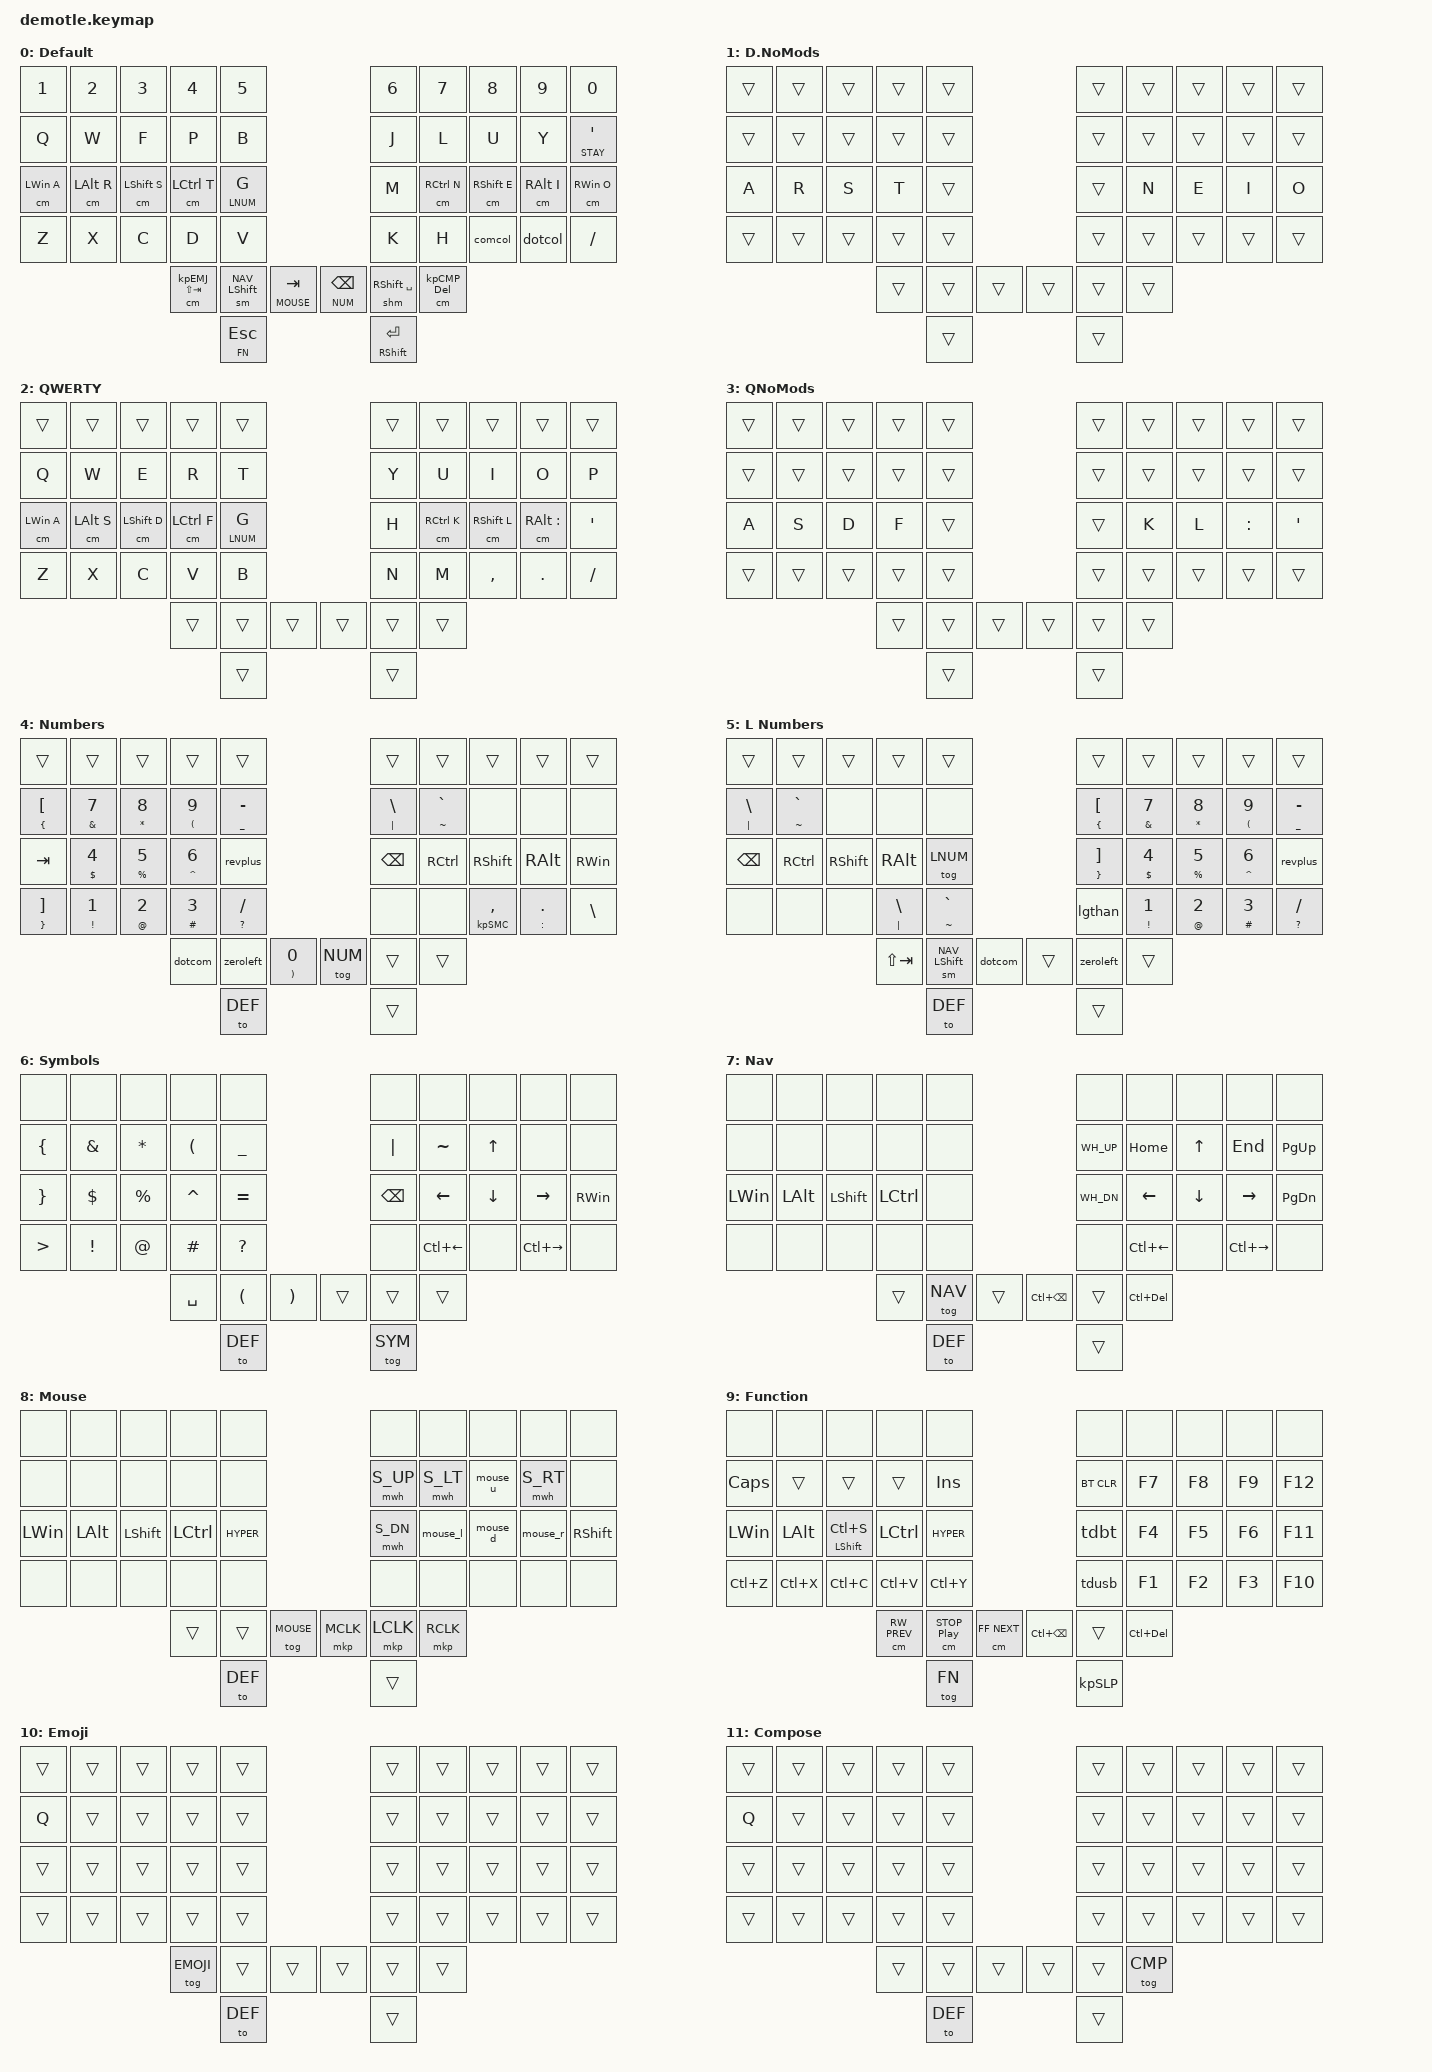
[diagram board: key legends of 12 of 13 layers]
/*
 * Copyright (c) 2023 Tom Butcher
 *
 * SPDX-License-Identifier: MIT
 */

 // standard build command: west build -b nice_nano_v2 -- -DSHIELD=demotle

 /* ********* TO DO *************
	* Once unicode works, create macros that change the layer and send the appropriate F key
	  (for helper image) at the same time.
 */

#include <behaviors.dtsi>
#include <dt-bindings/zmk/keys.h>
#include <dt-bindings/zmk/bt.h>
#include <dt-bindings/zmk/outputs.h>
#include <dt-bindings/zmk/ext_power.h>

// Layer Defs
#define DEF		0
#define DEF_NM	1
#define QWERTY	2
#define QWER_NM	3
#define NUM		4
#define LNUM	5
#define SYM		6
#define NAV		7
#define MOUSE	8
#define FN		9	
#define EMOJI	10	// Reserved for future use 
#define CMP		11	// Reserved for future use
#define STAY	12

// Mouse Key defs--For use until AHK can be ditched
#define WH_DN	(F16)
#define WH_UP	(F17)
// #define WH_L	(KP_N7)
// #define WH_R	(KP_N9)
// #define M_UP	(KP_N8)
// #define M_DN	(KP_N5)
// #define M_L		(KP_N4)
// #define M_R		(KP_N6)
// #define M_UP_SL	(LC(LG(LA(M_UP))))		// These move the mouse slowly
// #define M_DN_SL	(LC(LG(LA(M_DN))))
// #define M_R_SL	(LC(LG(LA(M_R))))
// #define M_L_SL	(LC(LG(LA(M_L))))
// #define M_MB	(KP_DIVIDE)
// #define M_LB	(KP_MINUS)
// #define M_RB	(KP_MULTIPLY)

// F Key subs (use with AHK)
#define KP_PLS	(F18)
#define KP_COM	(F19)
#define KP_SMC	(F20)
#define KP_EMJ	(F21)
#define KP_CMP	(F23)
#define KP_SLP	(LG(LA(LS(LC(APOS)))))

// Other defs
#define xxx		&none	
#define ___		&trans
#define HYPER	(LG(LA(LS(LCTRL))))		  // If I want to send a hypered key, then I might need to make a custom behavior
// #define HYPER	(LG(LA(LS(LCTRL))))   // Maybe try to make a custom mod kp?

#include <../boards/shields/space_invader/key_positions.h>
#include <../boards/shields/space_invader/mouse.dtsi>
#include <../boards/shields/space_invader/helper.h>
#include <../boards/shields/space_invader/behaviors.dtsi>
#include <../boards/shields/space_invader/combos.dtsi>

&mt { quick_tap_ms = <200>; };
&lt { quick_tap_ms = <200>; };

/ {
	conditional_layers {
        compatible = "zmk,conditional-layers";
        tri_layer {
            if-layers = <1 2>;
            then-layer = <3>;
        };
    };

	keymap {
		compatible = "zmk,keymap";

							// -------------------------------------------------TEMPLATE-------------------------------------------------
							// |      |      |      |      |      |                                  |      |      |      |      |      |
							// |      |      |      |      |      |                                  |      |      |      |      |      |
							// |      |      |      |      |      |             |      |             |      |      |      |      |      |
							// |      |------|      |      |      |      |      	          |      |      |      |      |------|      |
							// |----------------------------------|      |      |      |      |      |----------------------------------|
							// ----------------------------------------------------------------------------------------------------------

//------------------------------------------------------------------------------------------------EMPTY TEMPLATE-----------------------------------------------------------------------------------------------\\

//╭───────────────┬───────────────┬───────────────┬───────────────┬───────────────╮									  ╭───────────────┬───────────────┬───────────────┬───────────────┬───────────────╮

//├───────────────┼───────────────┼───────────────┼───────────────┼───────────────┤									  ├───────────────┼───────────────┼───────────────┼───────────────┼───────────────┤

//├───────────────┼───────────────┼───────────────┼───────────────┼───────────────┤									  ├───────────────┼───────────────┼───────────────┼───────────────┼───────────────┤

//├───────────────┼───────────────┼───────────────┼───────────────┼───────────────┤									  ├───────────────┼───────────────┼───────────────┼───────────────┼───────────────┤

//╰───────────────┴───────────────┴───────────────┼───────────────┼───────────────╰───────────────╮	  ╭───────────────╯───────────────┼───────────────┼───────────────┴───────────────┴───────────────╯
											 
//												  ╰───────────────┼───────────────┼───────────────╯	  ╰───────────────┼───────────────┼───────────────╯

//														  		  ╰───────────────╯									  ╰───────────────╯



		default_layer { 
			label = "Default";
			// -------------------------------------------------COLEMAK--------------------------------------------------
			// |  Q   |  W   |  F   |  P   |  B   |                                  |  J   |  L   |  U   |  Y   |  '"  |
			// |  A   |  R   |  S   |  T   |  G   |                                  |  M   |  N   |  E   |  I   |  O   |
			// |  Z   |  X   |  C   |  D   |  V   |             | Mute |             |  K   |  H   |  ,;  |  .:  |  /?  |  // In the future, maybe change back to interobang
			// |  Esc |------| Home |ShftTb|StckSh| Tab  |      	          | Bspc | Space| Del  |  End |------|  Del |  // Although maybe slash is more common than exclamation mark?
			// |----------------------------------|  Up  | Left | Enter| Right| Down |----------------------------------|
			// ----------------------------------------------------------------------------------------------------------
			// ------------------------------------------------HOLD LAYER------------------------------------------------
			// |      |      |      |      |      |                                  |      |      |      |      | Stay |
			// | LWin | LAlt | LShft| LCtrl| LNum |                                  |      | RCtrl| RShft| RAlt | RWin |
			// |      |      |      |      |      |             |      |             |      |      |      |      |      |
			// |  Fn  |------| LCtrl| Emoji| Nav  | Mouse|      	          | Num  | RShft| Cmp  | Sym  |------| Media|
			// |----------------------------------|      |      |      |      |      |----------------------------------|
			// ----------------------------------------------------------------------------------------------------------

			bindings = <
//-----------------------------------------------------------------------------------------------COLEMAK---------------------------------------------------------------------------------------------\\

//╭───────────────┬───────────────┬───────────────┬───────────────┬───────────────╮									  ╭───────────────┬───────────────┬───────────────┬───────────────┬───────────────╮
	&kp N1			&kp N2			&kp N3			&kp N4			&kp N5												&kp N6			&kp N7			&kp N8			&kp N9			&kp N0
//├───────────────┼───────────────┼───────────────┼───────────────┼───────────────┤									  ├───────────────┼───────────────┼───────────────┼───────────────┼───────────────┤
	&kp Q			&kp W			&kp F			&kp P			&kp B												&kp J			&kp L			&kp U			&kp Y			&lt STAY APOS	// &tdq
//├───────────────┼───────────────┼───────────────┼───────────────┼───────────────┤									  ├───────────────┼───────────────┼───────────────┼───────────────┼───────────────┤
	&cm LWIN A		&cm LALT R		&cm LSHFT S		&cm LCTRL T		&lt LNUM G											&kp M			&cm RCTRL N		&cm RSHFT E		&cm RALT I		&cm RWIN O
//├───────────────┼───────────────┼───────────────┼───────────────┼───────────────┤									  ├───────────────┼───────────────┼───────────────┼───────────────┼───────────────┤
	&kp Z			&kp X			&kp C			&kp D			&kp V												&kp K			&kp H			&comcol			&dotcol			&kp SLASH
//╰───────────────┴───────────────┴───────────────┼───────────────┼───────────────╰───────────────╮	  ╭───────────────╯───────────────┼───────────────┼───────────────┴───────────────┴───────────────╯
												&cm KP_EMJ LS(TAB)	&sm NAV LSHFT 	&lt MOUSE TAB		&lt NUM BSPC	&shm RSHFT SPACE &cm KP_CMP DEL
//												  ╰───────────────┼───────────────┼───────────────╯	  ╰───────────────┴───────────────┴───────────────╯
																	&lt FN ESC											&mt RSHFT RET
//																  ╰───────────────╯									  ╰───────────────╯

			>;
		};

		default_no_mods_layer { // Just turns off homerow mods, so no need for the whole keymap diagram
			label = "D.NoMods";
			bindings = <___ ___ ___ ___ ___ ___ ___ ___ ___ ___
						___ ___ ___ ___ ___ ___ ___ ___ ___ ___
						&kp A &kp R &kp S &kp T ___ ___ &kp N &kp E &kp I &kp O
						___ ___ ___ ___ ___ ___ ___ ___ ___ ___
						___ ___ ___ ___ ___ ___ ___ ___>;
		};

		qwerty_layer {
			label = "QWERTY";
			bindings = <
//-----------------------------------------------------------------------------------------------QWERTY----------------------------------------------------------------------------------------------\\

//╭───────────────┬───────────────┬───────────────┬───────────────┬───────────────╮									  ╭───────────────┬───────────────┬───────────────┬───────────────┬───────────────╮
	___				___				___				___				___													___				___				___				___				___
//├───────────────┼───────────────┼───────────────┼───────────────┼───────────────┤									  ├───────────────┼───────────────┼───────────────┼───────────────┼───────────────┤
	&kp Q			&kp W			&kp E			&kp R			&kp T												&kp Y			&kp U			&kp I			&kp O			&kp P 			// &lt STAY APOS
//├───────────────┼───────────────┼───────────────┼───────────────┼───────────────┤									  ├───────────────┼───────────────┼───────────────┼───────────────┼───────────────┤
	&cm LWIN A		&cm LALT S		&cm LSHFT D		&cm LCTRL F		&lt LNUM G											&kp H			&cm RCTRL K		&cm RSHFT L		&cm RALT COLON 	&kp APOS
//├───────────────┼───────────────┼───────────────┼───────────────┼───────────────┤									  ├───────────────┼───────────────┼───────────────┼───────────────┼───────────────┤
	&kp Z			&kp X			&kp C			&kp V			&kp B												&kp N			&kp M			&kp COMMA		&kp DOT			&kp SLASH
//╰───────────────┴───────────────┴───────────────┼───────────────┼───────────────╰───────────────╮	  ╭───────────────╯───────────────┼───────────────┼───────────────┴───────────────┴───────────────╯
													___				___				___					___				___				___
//												  ╰───────────────┼───────────────┼───────────────╯	  ╰───────────────┴───────────────┴───────────────╯
																	___													___
//																  ╰───────────────╯									  ╰───────────────╯

			>;
		};

		qwerty_no_mods_layer { // Just turns off homerow mods, so no need for the whole keymap diagram
			label = "QNoMods";
			bindings = <___ ___ ___ ___ ___ ___ ___ ___ ___ ___
						___ ___ ___ ___ ___ ___ ___ ___ ___ ___
						&kp A &kp S &kp D &kp F ___ ___ &kp K &kp L &kp COLON &kp APOS
						___ ___ ___ ___ ___ ___ ___ ___ ___ ___
						___ ___ ___ ___ ___ ___ ___ ___ >;
		};

		number_layer {
			label = "Numbers";
			
			// --------------------------------------------------NUMBER--------------------------------------------------
			// |  [{  |  1!  |  2@  |  3#  |  -_  |                                  |      |  \|  |  `~  |      |      |
			// |  ]}  |  4$  |  5%  |  6^  |  =+  |                                  | BSPC | RCTRL| RSHFT| RALT | RWIN |
			// |  <>  |  7&  |  8*  |  9(  |  \|  |             |      |             |      |      |  ,;  |  .:  |      |
			// | DEF |------| SPACE|  .,  |  0(  |  0)  |      	          |      |      |      |      |------|      |
			// |----------------------------------|      |      |      |      |      |----------------------------------|
			// ----------------------------------------------------------------------------------------------------------

			bindings = < // All numbers use auto-shift for symbols
//---------------------------------------------------------------------------------------------------NUMBERS--------------------------------------------------------------------------------------------------\\

//╭───────────────┬───────────────┬───────────────┬───────────────┬───────────────╮								  ╭───────────────┬───────────────┬───────────────┬───────────────┬───────────────╮
	___			  ___			___			  ___			___																			  ___			___			  ___			___			  ___
//├───────────────┼───────────────┼───────────────┼───────────────┼───────────────┤								  ├───────────────┼───────────────┼───────────────┼───────────────┼───────────────┤
  	&as LBRC LBKT &as AMPS N7	&as ASTRK N8  &as LPAR N9 	&as UNDER MINUS																  &as PIPE BSLH &as TILDE GRAVE xxx		  	xxx			  xxx
//├───────────────┼───────────────┼───────────────┼───────────────┼───────────────┤								  ├───────────────┼───────────────┼───────────────┼───────────────┼───────────────┤
  	&kp TAB		  &as DLLR N4	&as PRCNT N5  &as CARET N6	&revplus																	  &kp BSPC		&kp RCTRL	  &kp RSHFT		&kp RALT	  &kp RWIN
//├───────────────┼───────────────┼───────────────┼───────────────┼───────────────┤								  ├───────────────┼───────────────┼───────────────┼───────────────┼───────────────┤
	&as RBRC RBKT &as EXCL N1	&as AT N2	  &as HASH N3	&as QMARK SLASH																  xxx			xxx		   &as KP_SMC COMMA &as COLON DOT &kp BSLH
//╰───────────────┴───────────────┴───────────────┼───────────────┼───────────────╰───────────────╮	  ╭───────────────╯───────────────┼───────────────┼───────────────┴───────────────┴───────────────╯
													  		&dotcom		&zeroleft	  &as RPAR N0			  &tog NUM		___			  ___
//														  ╰───────────────┼───────────────┼───────────────╯		╰───────────────┴───────────────┴───────────────╯
											&to DEF											___
//																		╰───────────────╯									  ╰───────────────╯
			>;

		};


		left_number_layer {
			label = "L Numbers";
			
			// -----------------------------------------------LEFT NUMBER------------------------------------------------
			// |  [{  |  1!  |  2@  |  3#  |  -_  |                                  |      |  \|  |  `~  |      |      |
			// |  ]}  |  4$  |  5%  |  6^  |  =+  |                                  | BSPC | RCTRL| RSHFT| RALT | RWIN |
			// |  <>  |  7&  |  8*  |  9(  |  \|  |             |      |             |      |      |  ,;  |  .:  |      |
			// | DEF |------| SPACE|  .,  |  0(  |  0)  |      	          |      |      |      |      |------|      |
			// |----------------------------------|      |      |      |      |      |----------------------------------|
			// ----------------------------------------------------------------------------------------------------------

			bindings = < // All numbers use auto-shift for symbols
//------------------------------------------------------------------------------------------------LEFT NUMBERS------------------------------------------------------------------------------------------------\\

//╭───────────────┬───────────────┬───────────────┬───────────────┬───────────────╮								  ╭───────────────┬───────────────┬───────────────┬───────────────┬───────────────╮
	___			  ___			___			  ___			___																			  ___			___			  ___			___			  ___
//├───────────────┼───────────────┼───────────────┼───────────────┼───────────────┤								  ├───────────────┼───────────────┼───────────────┼───────────────┼───────────────┤
  	&as PIPE BSLH &as TILDE GRAVE xxx		  xxx			xxx												&as LBRC LBKT &as AMPS N7	  &as ASTRK N8  &as LPAR N9	  &as UNDER MINUS
//├───────────────┼───────────────┼───────────────┼───────────────┼───────────────┤								  ├───────────────┼───────────────┼───────────────┼───────────────┼───────────────┤
  	&kp BSPC	  &kp RCTRL	  	&kp RSHFT	  &kp RALT		&tog LNUM																	  &as RBRC RBKT &as DLLR N4	  &as PRCNT N5  &as CARET N6  &revplus
//├───────────────┼───────────────┼───────────────┼───────────────┼───────────────┤								  ├───────────────┼───────────────┼───────────────┼───────────────┼───────────────┤
	xxx			  xxx			xxx			  &as PIPE BSLH &as TILDE GRAVE																  &lgthan		&as EXCL N1	  &as AT N2		&as HASH N3	  &as QMARK SLASH
//╰───────────────┴───────────────┴───────────────┼───────────────┼───────────────╰───────────────╮	  ╭───────────────╯───────────────┼───────────────┼───────────────┴───────────────┴───────────────╯
													  		&kp LS(TAB)	  &sm NAV LSHFT &dotcom			  	  ___			&zeroleft	  ___
//														  ╰───────────────┼───────────────┼───────────────╯		╰───────────────┴───────────────┴───────────────╯
											&to DEF											___
//																		╰───────────────╯									  ╰───────────────╯
			>;
		};

		symbol_layer {
			label = "Symbols";
			bindings = <
//---------------------------------------------------------------------------------------------------SYMBOLS--------------------------------------------------------------------------------------------------\\

//╭───────────────┬───────────────┬───────────────┬───────────────┬───────────────╮								  ╭───────────────┬───────────────┬───────────────┬───────────────┬───────────────╮
	xxx			  xxx			xxx			  xxx			xxx																			  xxx			xxx			  xxx			xxx			  xxx
//├───────────────┼───────────────┼───────────────┼───────────────┼───────────────┤								  ├───────────────┼───────────────┼───────────────┼───────────────┼───────────────┤
  	&kp LBRC	  &kp AMPS		&kp ASTRK	  &kp LPAR		&kp UNDER																	  &kp PIPE		&kp TILDE	  &kp UP			xxx			  xxx
//├───────────────┼───────────────┼───────────────┼───────────────┼───────────────┤								  ├───────────────┼───────────────┼───────────────┼───────────────┼───────────────┤
  	&kp RBRC	  &kp DLLR		&kp PRCNT	  &kp CARET		&kp EQUAL																	  &kp BSPC		&kp LEFT	  &kp DOWN    	&kp RIGHT	  &kp RWIN
//├───────────────┼───────────────┼───────────────┼───────────────┼───────────────┤								  ├───────────────┼───────────────┼───────────────┼───────────────┼───────────────┤
	&kp GT		  &kp EXCL		&kp AT		  &kp HASH		&kp QMARK																	  xxx			&kp LC(LEFT)  xxx			&kp LC(RIGHT)  xxx
//╰───────────────┴───────────────┴───────────────┼───────────────┼───────────────╰───────────────╮	  ╭───────────────╯───────────────┼───────────────┼───────────────┴───────────────┴───────────────╯
													  		&kp SPACE	  &kp LPAR		&kp RPAR			  ___			___			  ___
//														  ╰───────────────┼───────────────┼───────────────╯		╰───────────────┴───────────────┴───────────────╯
											&to DEF											&tog SYM
//																		╰───────────────╯									  ╰───────────────╯
			>;
		};

		navigation_layer {
			label = "Nav";
			bindings = <
//-------------------------------------------------------------------------------------------------NAVIGATION-------------------------------------------------------------------------------------------------\\

//╭───────────────┬───────────────┬───────────────┬───────────────┬───────────────╮								  ╭───────────────┬───────────────┬───────────────┬───────────────┬───────────────╮
	xxx			  xxx			xxx			  xxx			xxx																			  xxx			xxx			  xxx			xxx			  xxx
//├───────────────┼───────────────┼───────────────┼───────────────┼───────────────┤								  ├───────────────┼───────────────┼───────────────┼───────────────┼───────────────┤
  	xxx			  xxx			xxx			  xxx			xxx												&kp WH_UP   	&kp HOME	  &kp UP		&kp END		  &kp PG_UP
//├───────────────┼───────────────┼───────────────┼───────────────┼───────────────┤								  ├───────────────┼───────────────┼───────────────┼───────────────┼───────────────┤
  	&kp LWIN	  &kp LALT	 	&kp LSHFT	  &kp LCTRL		xxx												&kp WH_DN   	&kp LEFT	  &kp DOWN    	&kp RIGHT 	  &kp PG_DN
//├───────────────┼───────────────┼───────────────┼───────────────┼───────────────┤								  ├───────────────┼───────────────┼───────────────┼───────────────┼───────────────┤
	xxx			  xxx			xxx			  xxx			xxx																			  xxx			&kp LC(LEFT)  xxx			&kp LC(RIGHT) xxx	
//╰───────────────┴───────────────┴───────────────┼───────────────┼───────────────╰───────────────╮	  ╭───────────────╯───────────────┼───────────────┼───────────────┴───────────────┴───────────────╯
													  		___			  &tog NAV		___			  		  &kp LC(BSPC)	___			  &kp LC(DEL)
//														  ╰───────────────┼───────────────┼───────────────╯		╰───────────────┴───────────────┴───────────────╯
											&to DEF											___
//																		╰───────────────╯									  ╰───────────────╯

			>;
		};

		mouse_layer {
			label = "Mouse";
			bindings = <
//----------------------------------------------------------------------------------------------------MOUSE---------------------------------------------------------------------------------------------------\\

//╭───────────────┬───────────────┬───────────────┬───────────────┬───────────────╮								  ╭───────────────┬───────────────┬───────────────┬───────────────┬───────────────╮
	xxx			  xxx			xxx			  xxx			xxx																			  xxx			xxx			  xxx			xxx			  xxx
//├───────────────┼───────────────┼───────────────┼───────────────┼───────────────┤								  ├───────────────┼───────────────┼───────────────┼───────────────┼───────────────┤
  	xxx			  xxx			xxx			  xxx			xxx												&mwh S_UP		&mwh S_LT	  &mouse_u		&mwh S_RT 	  xxx	
//├───────────────┼───────────────┼───────────────┼───────────────┼───────────────┤								  ├───────────────┼───────────────┼───────────────┼───────────────┼───────────────┤
  	&kp LWIN	  &kp LALT		&kp LSHFT	  &kp LCTRL		&kp HYPER																	  &mwh S_DN		&mouse_l	  &mouse_d		&mouse_r	  &kp RSHFT	
//├───────────────┼───────────────┼───────────────┼───────────────┼───────────────┤								  ├───────────────┼───────────────┼───────────────┼───────────────┼───────────────┤
	xxx			  xxx			xxx			  xxx			xxx																			  xxx			xxx			  xxx			xxx			  xxx
//╰───────────────┴───────────────┴───────────────┼───────────────┼───────────────╰───────────────╮	  ╭───────────────╯───────────────┼───────────────┼───────────────┴───────────────┴───────────────╯
													  		___			  ___			&tog MOUSE	  		  &mkp MCLK		&mkp LCLK	  &mkp RCLK
//														  ╰───────────────┼───────────────┼───────────────╯		╰───────────────┴───────────────┴───────────────╯
											&to DEF											___
//																		╰───────────────╯									  ╰───────────────╯

			>;
		};

		function_layer { // Gonna need to fix stuff here
			label = "Function";
			bindings = <
//--------------------------------------------------------------------------------------------------FUNCTION--------------------------------------------------------------------------------------------------\\

//╭───────────────┬───────────────┬───────────────┬───────────────┬───────────────╮								  ╭───────────────┬───────────────┬───────────────┬───────────────┬───────────────╮
	xxx			  xxx			xxx			  xxx			xxx																			  xxx			xxx			  xxx			xxx			  xxx
//├───────────────┼───────────────┼───────────────┼───────────────┼───────────────┤								  ├───────────────┼───────────────┼───────────────┼───────────────┼───────────────┤
  	&kp CAPS	  ___	 		___			  ___			&kp INS											&bt BT_CLR	&kp F7		  &kp F8		&kp F9		  &kp F12
//├───────────────┼───────────────┼───────────────┼───────────────┼───────────────┤								  ├───────────────┼───────────────┼───────────────┼───────────────┼───────────────┤
  	&kp LWIN	  &kp LALT	 &mt LSHFT LC(S)  &kp LCTRL		&kp HYPER																	  &tdbt			&kp F4		  &kp F5		&kp F6		  &kp F11
//├───────────────┼───────────────┼───────────────┼───────────────┼───────────────┤								  ├───────────────┼───────────────┼───────────────┼───────────────┼───────────────┤
	&kp LC(Z)	  &kp LC(X)		&kp LC(C)	  &kp LC(V)		&kp LC(Y)   																  &tdusb		&kp F1		  &kp F2		&kp F3		  &kp F10
//╰───────────────┴───────────────┴───────────────┼───────────────┼───────────────╰───────────────╮	  ╭───────────────╯───────────────┼───────────────┼───────────────┴───────────────┴───────────────╯
													  	&cm C_RW C_PREV  &cm C_STOP C_PP &cm C_FF C_NEXT	  &kp LC(BSPC)	___			  &kp LC(DEL)
//														  ╰───────────────┼───────────────┼───────────────╯		╰───────────────┴───────────────┴───────────────╯
											&tog FN											&kp KP_SLP
//																		╰───────────────╯									  ╰───────────────╯
			>;
		};

		emoji_layer { // todo: Unicode (including emoji) not yet implemented in ZMK. Maybe try using AHK in the meantime?
			label = "Emoji";
			bindings = <
//----------------------------------------------------------------------------------------------------EMOJI---------------------------------------------------------------------------------------------------\\

//╭───────────────┬───────────────┬───────────────┬───────────────┬───────────────╮								  ╭───────────────┬───────────────┬───────────────┬───────────────┬───────────────╮
	___			  ___			___			  ___			___																			  ___			___			  ___			___			  ___
//├───────────────┼───────────────┼───────────────┼───────────────┼───────────────┤								  ├───────────────┼───────────────┼───────────────┼───────────────┼───────────────┤
  	&kp Q		  ___			___			  ___			___																			  ___			___			  ___			___			  ___	
//├───────────────┼───────────────┼───────────────┼───────────────┼───────────────┤								  ├───────────────┼───────────────┼───────────────┼───────────────┼───────────────┤
  	___			  ___			___			  ___			___																			  ___			___			  ___			___			  ___	
//├───────────────┼───────────────┼───────────────┼───────────────┼───────────────┤								  ├───────────────┼───────────────┼───────────────┼───────────────┼───────────────┤
	___			  ___			___			  ___			___																			  ___			___			  ___			___			  ___	
//╰───────────────┴───────────────┴───────────────┼───────────────┼───────────────╰───────────────╮	  ╭───────────────╯───────────────┼───────────────┼───────────────┴───────────────┴───────────────╯
													  		&tog EMOJI	  ___			___					  ___			___			  ___	
//														  ╰───────────────┼───────────────┼───────────────╯		╰───────────────┴───────────────┴───────────────╯
											&to DEF											___
//																		╰───────────────╯									  ╰───────────────╯
			>;
		};

		compose_layer { // todo: unicode not yet implemented in ZMK. Maybe try using AHK in the meantime?
			label = "Compose";
			bindings = <
//---------------------------------------------------------------------------------------------------COMPOSE--------------------------------------------------------------------------------------------------\\

//╭───────────────┬───────────────┬───────────────┬───────────────┬───────────────╮								  ╭───────────────┬───────────────┬───────────────┬───────────────┬───────────────╮
	___			  ___			___			  ___			___																			  ___			___			  ___			___			  ___
//├───────────────┼───────────────┼───────────────┼───────────────┼───────────────┤								  ├───────────────┼───────────────┼───────────────┼───────────────┼───────────────┤
  	&kp Q		  ___			___			  ___			___																			  ___			___			  ___			___			  ___	
//├───────────────┼───────────────┼───────────────┼───────────────┼───────────────┤								  ├───────────────┼───────────────┼───────────────┼───────────────┼───────────────┤
  	___			  ___			___			  ___			___																			  ___			___			  ___			___			  ___	
//├───────────────┼───────────────┼───────────────┼───────────────┼───────────────┤								  ├───────────────┼───────────────┼───────────────┼───────────────┼───────────────┤
	___			  ___			___			  ___			___																			  ___			___			  ___			___			  ___	
//╰───────────────┴───────────────┴───────────────┼───────────────┼───────────────╰───────────────╮	  ╭───────────────╯───────────────┼───────────────┼───────────────┴───────────────┴───────────────╯
													  		___			  ___			___					  ___			___			  &tog CMP	
//														  ╰───────────────┼───────────────┼───────────────╯		╰───────────────┴───────────────┴───────────────╯
											&to DEF											___
//																		╰───────────────╯									  ╰───────────────╯
			>;
		};

		stay_layer {	// This layer is for toggling the layers (rather than just holding them on). Can be replaced in the future with double-taps or something
			label = "Stay";
			bindings = <
//-------------------------------------------------------------------------------------------------STAY  LAYER------------------------------------------------------------------------------------------------\\

//╭───────────────┬───────────────┬───────────────┬───────────────┬───────────────╮								  ╭───────────────┬───────────────┬───────────────┬───────────────┬───────────────╮
	___			  ___			___			  ___			___																			  ___			___			  ___			___			  ___
//├───────────────┼───────────────┼───────────────┼───────────────┼───────────────┤								  ├───────────────┼───────────────┼───────────────┼───────────────┼───────────────┤
  	&kp Q		  ___			___			  ___			___																			  ___			___			  ___			___			  ___	
//├───────────────┼───────────────┼───────────────┼───────────────┼───────────────┤								  ├───────────────┼───────────────┼───────────────┼───────────────┼───────────────┤
  	___			  ___			___			  ___			___																			  ___			___			  ___			___			  ___	
//├───────────────┼───────────────┼───────────────┼───────────────┼───────────────┤								  ├───────────────┼───────────────┼───────────────┼───────────────┼───────────────┤
	___			  ___			___			  ___			___																			  ___			___			  ___			___			  ___	
//╰───────────────┴───────────────┴───────────────┼───────────────┼───────────────╰───────────────╮	  ╭───────────────╯───────────────┼───────────────┼───────────────┴───────────────┴───────────────╯
													  		&tog EMOJI	  &tog NAV		&tog MOUSE			  &tog NUM		&kp CAPS 	  &tog CMP	
//														  ╰───────────────┼───────────────┼───────────────╯		╰───────────────┴───────────────┴───────────────╯
											&tog FN											&tog SYM
//																		╰───────────────╯									  ╰───────────────╯
			>;
		};
	};
};
